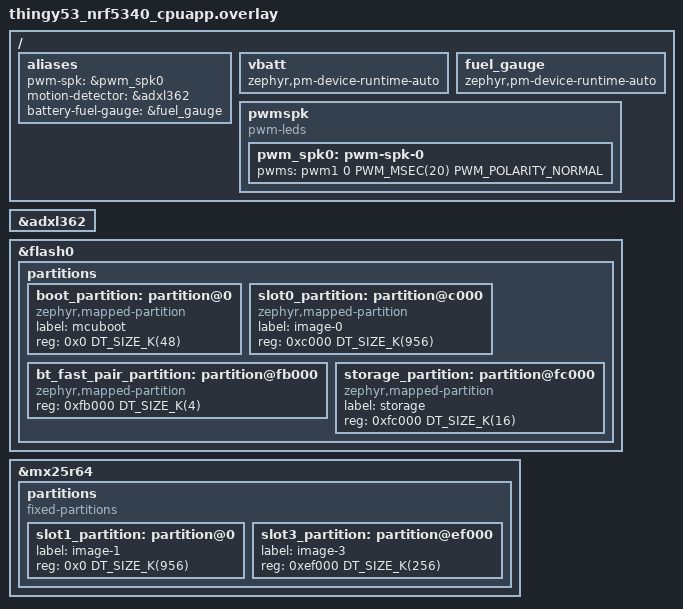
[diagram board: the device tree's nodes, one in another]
/*
 * Copyright (c) 2024-2026 Nordic Semiconductor ASA
 *
 * SPDX-License-Identifier: LicenseRef-Nordic-5-Clause
 */

/ {
	aliases {
		pwm-spk = &pwm_spk0;
		motion-detector = &adxl362;
		battery-fuel-gauge = &fuel_gauge;
	};

	vbatt {
		status = "okay";
		zephyr,pm-device-runtime-auto;
	};

	fuel_gauge {
		status = "okay";
		zephyr,pm-device-runtime-auto;
	};

	pwmspk {
		compatible = "pwm-leds";

		pwm_spk0: pwm-spk-0 {
			pwms = <&pwm1 0 PWM_MSEC(20) PWM_POLARITY_NORMAL>;
		};
	};
};

&adxl362 {
	status = "okay";
};

&flash0 {
	/* Redefine the "partitions" DTS node. */
	/delete-node/ partitions;

	partitions {
		ranges;
		#address-cells = <1>;
		#size-cells = <1>;

		boot_partition: partition@0 {
			compatible = "zephyr,mapped-partition";
			label = "mcuboot";
			reg = <0x0 DT_SIZE_K(48)>;
		};

		slot0_partition: partition@c000 {
			compatible = "zephyr,mapped-partition";
			label = "image-0";
			reg = <0xc000 DT_SIZE_K(956)>;
		};

		bt_fast_pair_partition: partition@fb000 {
			compatible = "zephyr,mapped-partition";
			reg = <0xfb000 DT_SIZE_K(4)>;
		};

		storage_partition: partition@fc000 {
			compatible = "zephyr,mapped-partition";
			label = "storage";
			reg = <0xfc000 DT_SIZE_K(16)>;
		};
	};
};

&mx25r64 {
	status = "okay";

	partitions {
		compatible = "fixed-partitions";
		#address-cells = <1>;
		#size-cells = <1>;

		slot1_partition: partition@0 {
			label = "image-1";
			reg = <0x0 DT_SIZE_K(956)>;
		};

		/*
		 * The network core secondary slot must be the same size as
		 * the corresponding RAM-backed slot2_partition defined in
		 * nrf/modules/mcuboot/flash_sim.overlay (256 KB). This size
		 * is aligned with the legacy Partition Manager
		 * mcuboot_secondary_1 partition to keep DFU update packages
		 * backwards compatible.
		 */
		slot3_partition: partition@ef000 {
			label = "image-3";
			reg = <0xef000 DT_SIZE_K(256)>;
		};
	};
};
